# f29h85x_adc_global_regs register map
Vendor: Texas Instruments
Peripheral module from a debugger description file (folder C29).
Registers are 32-bit, read-write, no defined reset value unless marked. A register's access mark holds for its fields unless they carry their own. Offsets are as the file gives them; lines under a group give offsets from that group; [hi:lo] are bit positions; {n}, {i} and the like mark numbered series; 'fields as' and 'values as' point back to an identical list; <NAME> marks a mode.

## ADC_GLOBAL_REGS — ADC GLOBAL Registers
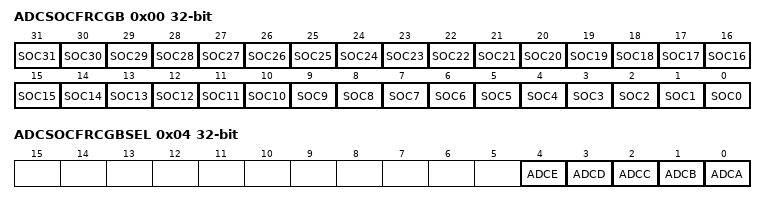
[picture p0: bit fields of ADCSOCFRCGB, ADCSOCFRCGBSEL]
0x00 ADCSOCFRCGB — ADC Global SOC Force
  [n] SOC{n} (n=0..31) — Generate synchronous SW trigger for SOC{n}
0x04 ADCSOCFRCGBSEL — ADC Global SOC Force Select
  [4] ADCE — Generate synchronous SW trigger for ADCE
  [3] ADCD — Generate synchronous SW trigger for ADCD
  [2] ADCC — Generate synchronous SW trigger for ADCC
  [1] ADCB — Generate synchronous SW trigger for ADCB
  [0] ADCA — Generate synchronous SW trigger for ADCA
0x08 PARITY_TEST_ALT1 — Enables parity test
  [3:0] TESTEN — Parity test enable configuration
